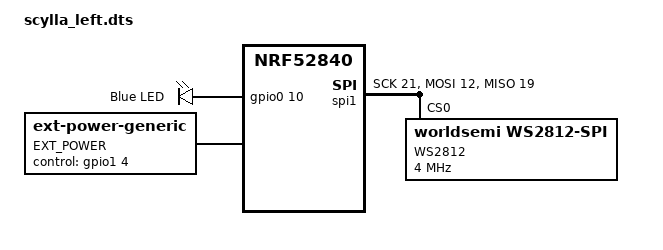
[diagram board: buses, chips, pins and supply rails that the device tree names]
/*
 * Copyright (c) 2021 Thys de Wet (vattern)
 *
 * SPDX-License-Identifier: MIT
 */

/dts-v1/;
#include <nordic/nrf52840_qiaa.dtsi>
#include <dt-bindings/zmk/matrix_transform.h>
#include <dt-bindings/led/led.h>
#include "scylla.dtsi"
/ {

leds {
  compatible = "gpio-leds";
  blue_led: led_0 {
    gpios = <&gpio0 10 GPIO_ACTIVE_HIGH>;
    label = "Blue LED";
  };
};

ext-power {
    compatible = "zmk,ext-power-generic";
    label = "EXT_POWER";
    control-gpios = <&gpio1 4 GPIO_ACTIVE_HIGH>;
    init-delay-ms = <50>;
  };
  
kscan0: kscan {
    col-gpios
        = <&gpio0 3  (GPIO_ACTIVE_HIGH | GPIO_PULL_DOWN)>
        , <&gpio0 2  (GPIO_ACTIVE_HIGH | GPIO_PULL_DOWN)>
        , <&gpio0 29 (GPIO_ACTIVE_HIGH | GPIO_PULL_DOWN)>
        , <&gpio1 4  (GPIO_ACTIVE_HIGH | GPIO_PULL_DOWN)>
        , <&gpio1 6  (GPIO_ACTIVE_HIGH | GPIO_PULL_DOWN)>
        , <&gpio0 9  (GPIO_ACTIVE_HIGH | GPIO_PULL_DOWN)>
        ;
    row-gpios
        = <&gpio0 28 (GPIO_ACTIVE_HIGH )>
        , <&gpio1 15  (GPIO_ACTIVE_HIGH )>
        , <&gpio1 10 (GPIO_ACTIVE_HIGH )>
        , <&gpio1 13  (GPIO_ACTIVE_HIGH )>
        , <&gpio0 10  (GPIO_ACTIVE_HIGH )>
        ;
        };
    };

&spi1 {
  compatible = "nordic,nrf-spim";
  status = "okay";
  mosi-pin = <12>;
  // Unused pins, needed for SPI definition, but not used by the ws2812 driver itself.
  sck-pin = <21>;
  miso-pin = <19>;

  led_strip: ws2812@0 {
    compatible = "worldsemi,ws2812-spi";
    label = "WS2812";

    /* SPI */
    reg = <0>; /* ignored, but necessary for SPI bindings */
    spi-max-frequency = <4000000>;

    /* WS2812 */
    chain-length = <29>; /* number of LEDs */
    spi-one-frame = <0x70>;
    spi-zero-frame = <0x40>;
    color-mapping = <LED_COLOR_ID_GREEN
                          LED_COLOR_ID_RED
                          LED_COLOR_ID_BLUE>;
  };
};    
